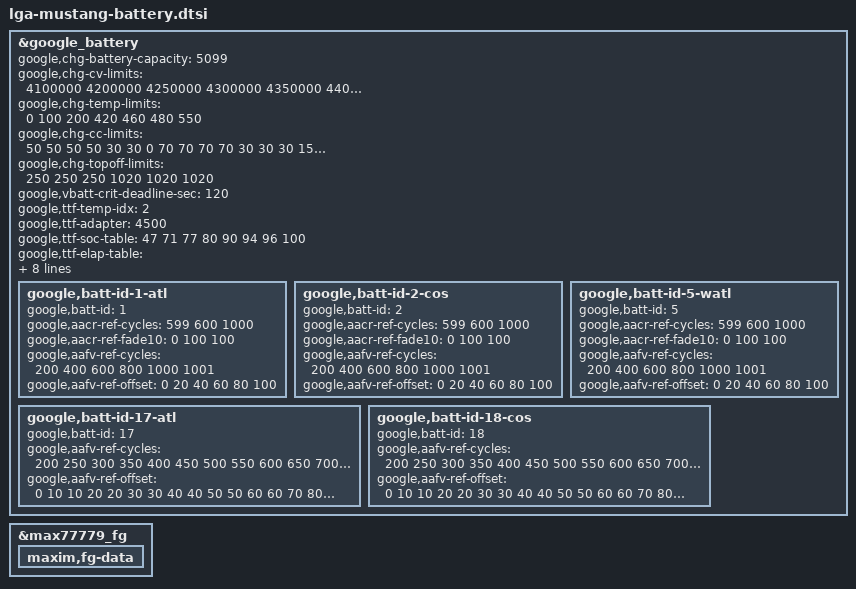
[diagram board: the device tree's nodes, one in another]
// SPDX-License-Identifier: GPL-2.0-only
/*
 * Battery device tree entries specific to Mustang
 *
 * Copyright 2024 Google LLC
 *
 */

&google_battery {
	google,chg-battery-capacity = <5099>;

	google,chg-cv-limits = <4100000 4200000 4250000 4300000 4350000 4400000 4500000>;
	google,chg-temp-limits = <0 100 200 420 460 480 550>;
	google,chg-cc-limits = <
		 50   50   50   50   30   30    0
		 70   70   70   70   30   30   30
		150  150  150  150  150   50   50
		150  150  150   50   50   50   50
		 50   50   50   50    0    0    0
		 50   30    0    0    0    0    0
	>;

	google,chg-topoff-limits = <250 250 250 1020 1020 1020>;

	google,vbatt-crit-deadline-sec = <120>;

	google,ttf-temp-idx= <2>;
	google,ttf-adapter = <4500>;
	google,ttf-soc-table =  <47 71 77 80 90  94  96 100>;
	google,ttf-elap-table = <22 25 39 59 80 135 209  90>;
	google,ttf-tier-table = <0>;
	google,ttf-report-max-ratio = <0>;

	google,aacr-config = <1>; /* enabled, no opt out */
	google,aafv-config = <1>; /* enabled, no opt out */

	/* 90% after 600 cycles, 80% after 1000 cycles */
	google,aacr-algo = <3>;
	google,aacr-cliff-capacity-rate = <80>;
	google,aacr-cycle-max = <1000>;

	google,batt-id-1-atl {
		google,batt-id = <1>;
		google,aacr-ref-cycles = <599 600 1000>;
		google,aacr-ref-fade10 = <  0 100  100>;
		google,aafv-ref-cycles = <200 400 600 800 1000 1001>;
		google,aafv-ref-offset = <  0  20  40  60   80  100>;
	};
	google,batt-id-2-cos {
		google,batt-id = <2>;
		google,aacr-ref-cycles = <599 600 1000>;
		google,aacr-ref-fade10 = <  0 100  100>;
		google,aafv-ref-cycles = <200 400 600 800 1000 1001>;
		google,aafv-ref-offset = <  0  20  40  60   80  100>;
	};
	google,batt-id-5-watl {
		google,batt-id = <5>;
		google,aacr-ref-cycles = <599 600 1000>;
		google,aacr-ref-fade10 = <  0 100  100>;
		google,aafv-ref-cycles = <200 400 600 800 1000 1001>;
		google,aafv-ref-offset = <  0  20  40  60   80  100>;
	};
	google,batt-id-17-atl {
		google,batt-id = <17>;
		google,aafv-ref-cycles = <
			200  250  300  350  400  450  500  550
			600  650  700  750  800  850  900  950
		>;
		google,aafv-ref-offset = <
			  0  10  10  20  20  30  30  40
			 40  50  50  60  60  70  80  90
		>;
	};
	google,batt-id-18-cos {
		google,batt-id = <18>;
		google,aafv-ref-cycles = <
			200  250  300  350  400  450  500  550
			600  650  700  750  800  850  900  950
		>;
		google,aafv-ref-offset = <
			  0  10  10  20  20  30  30  40
			 40  50  50  60  60  70  80  90
		>;
	};
};

&max77779_fg {
	maxim,fg-data {
		#include "lga-mustang-battery-data.dtsi"
	};
};
